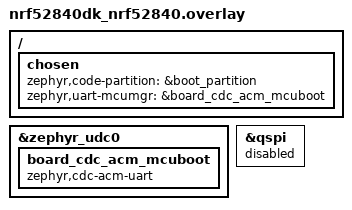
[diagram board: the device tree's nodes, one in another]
/*
 * Copyright (c) 2026 RAKwireless Technology Limited
 * Author: sercan.erat@rakwireless.com
 * SPDX-License-Identifier: Apache-2.0
 */

/* Same flash layout as the loader.  */
#include "../../../../variants/nrf52840dk_nrf52840/nrf52840dk_nrf52840_partitions.dtsi"
/* Same boot-mode retention area as the loader. */
#include "../../../../variants/nrf52840dk_nrf52840/nrf52840dk_nrf52840_bootmode.dtsi"

/ {
	chosen {
		zephyr,code-partition = &boot_partition;
		zephyr,uart-mcumgr = &board_cdc_acm_mcuboot;
	};
};

&zephyr_udc0 {
	board_cdc_acm_mcuboot: board_cdc_acm_mcuboot {
		compatible = "zephyr,cdc-acm-uart";
		status = "okay";
	};
};

/* Like the loader, leave the MX25R64 QSPI flash unused. */
/delete-node/ &mx25r64;

&qspi {
	status = "disabled";
};
